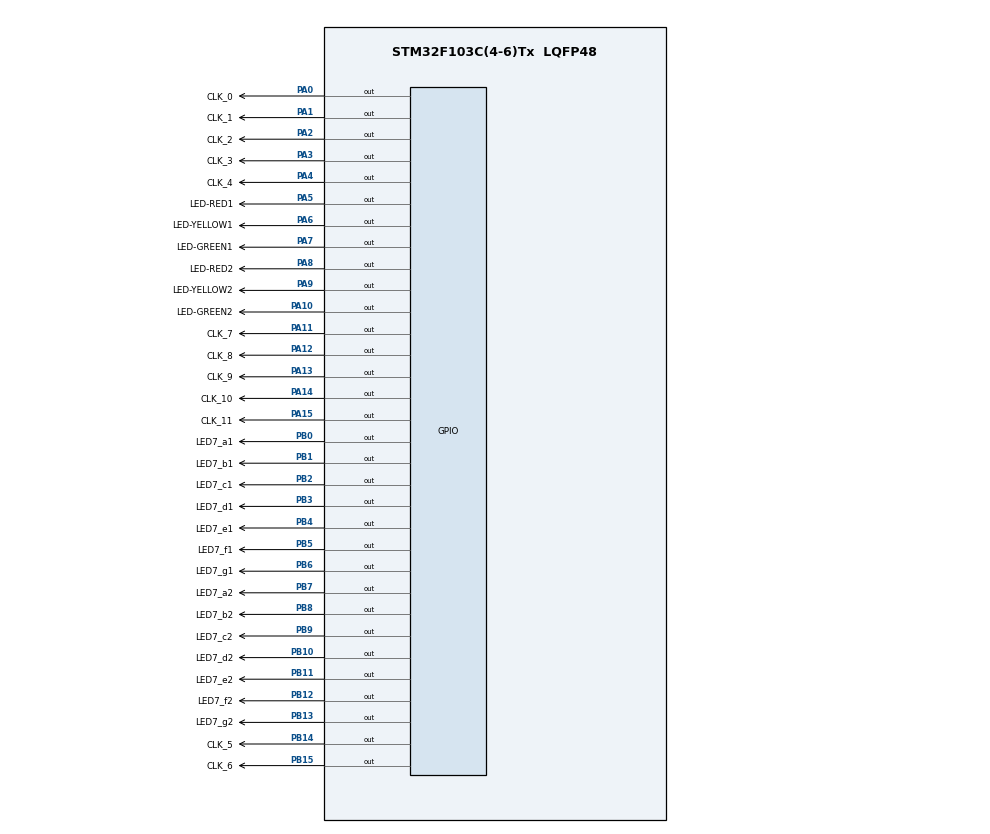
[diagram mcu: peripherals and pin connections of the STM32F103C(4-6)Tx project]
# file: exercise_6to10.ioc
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Mcu.Family=STM32F1
Mcu.Name=STM32F103C(4-6)Tx
Mcu.Package=LQFP48
NVIC.PriorityGroup=NVIC_PRIORITYGROUP_4
PA0-WKUP.GPIO_Label=CLK_0
PA0-WKUP.Signal=GPIO_Output
PA1.GPIO_Label=CLK_1
PA1.Signal=GPIO_Output
PA10.GPIO_Label=LED-GREEN2
PA10.Signal=GPIO_Output
PA11.GPIO_Label=CLK_7
PA11.Signal=GPIO_Output
PA12.GPIO_Label=CLK_8
PA12.Signal=GPIO_Output
PA13.GPIO_Label=CLK_9
PA13.Signal=GPIO_Output
PA14.GPIO_Label=CLK_10
PA14.Signal=GPIO_Output
PA15.GPIO_Label=CLK_11
PA15.Signal=GPIO_Output
PA2.GPIO_Label=CLK_2
PA2.Signal=GPIO_Output
PA3.GPIO_Label=CLK_3
PA3.Signal=GPIO_Output
PA4.GPIO_Label=CLK_4
PA4.Signal=GPIO_Output
PA5.GPIO_Label=LED-RED1
PA5.Signal=GPIO_Output
PA6.GPIO_Label=LED-YELLOW1
PA6.Signal=GPIO_Output
PA7.GPIO_Label=LED-GREEN1
PA7.Signal=GPIO_Output
PA8.GPIO_Label=LED-RED2
PA8.Signal=GPIO_Output
PA9.GPIO_Label=LED-YELLOW2
PA9.Signal=GPIO_Output
PB0.GPIO_Label=LED7_a1
PB0.Signal=GPIO_Output
PB1.GPIO_Label=LED7_b1
PB1.Signal=GPIO_Output
PB10.GPIO_Label=LED7_d2
PB10.Signal=GPIO_Output
PB11.GPIO_Label=LED7_e2
PB11.Signal=GPIO_Output
PB12.GPIO_Label=LED7_f2
PB12.Signal=GPIO_Output
PB13.GPIO_Label=LED7_g2
PB13.Signal=GPIO_Output
PB14.GPIO_Label=CLK_5
PB14.Signal=GPIO_Output
PB15.GPIO_Label=CLK_6
PB15.Signal=GPIO_Output
PB2.GPIO_Label=LED7_c1
PB2.Signal=GPIO_Output
PB3.GPIO_Label=LED7_d1
PB3.Signal=GPIO_Output
PB4.GPIO_Label=LED7_e1
PB4.Signal=GPIO_Output
PB5.GPIO_Label=LED7_f1
PB5.Signal=GPIO_Output
PB6.GPIO_Label=LED7_g1
PB6.Signal=GPIO_Output
PB7.GPIO_Label=LED7_a2
PB7.Signal=GPIO_Output
PB8.GPIO_Label=LED7_b2
PB8.Signal=GPIO_Output
PB9.GPIO_Label=LED7_c2
PB9.Signal=GPIO_Output
ProjectManager.HeapSize=0x200
ProjectManager.StackSize=0x400
ProjectManager.TargetToolchain=STM32CubeIDE
RCC.APB1Freq_Value=8000000
RCC.APB2Freq_Value=8000000
VP_SYS_VS_ND.Mode=No_Debug
board=custom

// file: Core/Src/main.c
/* USER CODE BEGIN Header */
/**
  ******************************************************************************
  * @file           : main.c
  * @brief          : Main program body
  ******************************************************************************
  * @attention
  *
  * <h2><center>&copy; Copyright (c) 2024 STMicroelectronics.
  * All rights reserved.</center></h2>
  *
  * This software component is licensed by ST under BSD 3-Clause license,
  * the "License"; You may not use this file except in compliance with the
  * License. You may obtain a copy of the License at:
  *                        opensource.org/licenses/BSD-3-Clause
  *
  ******************************************************************************
  */
/* USER CODE END Header */
#include "main.h"
#include "exercise_6to10.h"

void SystemClock_Config(void);
static void MX_GPIO_Init(void);

int main(void)
{

  /* MCU Configuration--------------------------------------------------------*/

  /* Reset of all peripherals, Initializes the Flash interface and the Systick. */
  HAL_Init();

  /* Configure the system clock */
  SystemClock_Config();

  /* Initialize all configured peripherals */
  MX_GPIO_Init();

  /* Infinite loop */
  /* USER CODE BEGIN WHILE */
  clearAllClock(); 				// Initial
  while (1)
  {
    /* USER CODE END WHILE */
	displayClock();
	HAL_Delay(10);
  }
}

void SystemClock_Config(void)
{
  RCC_OscInitTypeDef RCC_OscInitStruct = {0};
  RCC_ClkInitTypeDef RCC_ClkInitStruct = {0};

  /** Initializes the RCC Oscillators according to the specified parameters
  * in the RCC_OscInitTypeDef structure.
  */
  RCC_OscInitStruct.OscillatorType = RCC_OSCILLATORTYPE_HSI;
  RCC_OscInitStruct.HSIState = RCC_HSI_ON;
  RCC_OscInitStruct.HSICalibrationValue = RCC_HSICALIBRATION_DEFAULT;
  RCC_OscInitStruct.PLL.PLLState = RCC_PLL_NONE;
  if (HAL_RCC_OscConfig(&RCC_OscInitStruct) != HAL_OK)
  {
    Error_Handler();
  }
  /** Initializes the CPU, AHB and APB buses clocks
  */
  RCC_ClkInitStruct.ClockType = RCC_CLOCKTYPE_HCLK|RCC_CLOCKTYPE_SYSCLK
                              |RCC_CLOCKTYPE_PCLK1|RCC_CLOCKTYPE_PCLK2;
  RCC_ClkInitStruct.SYSCLKSource = RCC_SYSCLKSOURCE_HSI;
  RCC_ClkInitStruct.AHBCLKDivider = RCC_SYSCLK_DIV1;
  RCC_ClkInitStruct.APB1CLKDivider = RCC_HCLK_DIV1;
  RCC_ClkInitStruct.APB2CLKDivider = RCC_HCLK_DIV1;

  if (HAL_RCC_ClockConfig(&RCC_ClkInitStruct, FLASH_LATENCY_0) != HAL_OK)
  {
    Error_Handler();
  }
}

static void MX_GPIO_Init(void)
{
  GPIO_InitTypeDef GPIO_InitStruct = {0};

  /* GPIO Ports Clock Enable */
  __HAL_RCC_GPIOA_CLK_ENABLE();
  __HAL_RCC_GPIOB_CLK_ENABLE();

  /*Configure GPIO pin Output Level */
  HAL_GPIO_WritePin(GPIOA, CLK_0_Pin|CLK_1_Pin|CLK_2_Pin|CLK_3_Pin
                          |CLK_4_Pin|LED_RED1_Pin|LED_YELLOW1_Pin|LED_GREEN1_Pin
                          |LED_RED2_Pin|LED_YELLOW2_Pin|LED_GREEN2_Pin|CLK_7_Pin
                          |CLK_8_Pin|CLK_9_Pin|CLK_10_Pin|CLK_11_Pin, GPIO_PIN_RESET);

  /*Configure GPIO pin Output Level */
  HAL_GPIO_WritePin(GPIOB, LED7_a1_Pin|LED7_b1_Pin|LED7_c1_Pin|LED7_d2_Pin
                          |LED7_e2_Pin|LED7_f2_Pin|LED7_g2_Pin|CLK_5_Pin
                          |CLK_6_Pin|LED7_d1_Pin|LED7_e1_Pin|LED7_f1_Pin
                          |LED7_g1_Pin|LED7_a2_Pin|LED7_b2_Pin|LED7_c2_Pin, GPIO_PIN_RESET);

  /*Configure GPIO pins : CLK_0_Pin CLK_1_Pin CLK_2_Pin CLK_3_Pin
                           CLK_4_Pin LED_RED1_Pin LED_YELLOW1_Pin LED_GREEN1_Pin
                           LED_RED2_Pin LED_YELLOW2_Pin LED_GREEN2_Pin CLK_7_Pin
                           CLK_8_Pin CLK_9_Pin CLK_10_Pin CLK_11_Pin */
  GPIO_InitStruct.Pin = CLK_0_Pin|CLK_1_Pin|CLK_2_Pin|CLK_3_Pin
                          |CLK_4_Pin|LED_RED1_Pin|LED_YELLOW1_Pin|LED_GREEN1_Pin
                          |LED_RED2_Pin|LED_YELLOW2_Pin|LED_GREEN2_Pin|CLK_7_Pin
                          |CLK_8_Pin|CLK_9_Pin|CLK_10_Pin|CLK_11_Pin;
  GPIO_InitStruct.Mode = GPIO_MODE_OUTPUT_PP;
  GPIO_InitStruct.Pull = GPIO_NOPULL;
  GPIO_InitStruct.Speed = GPIO_SPEED_FREQ_LOW;
  HAL_GPIO_Init(GPIOA, &GPIO_InitStruct);

  /*Configure GPIO pins : LED7_a1_Pin LED7_b1_Pin LED7_c1_Pin LED7_d2_Pin
                           LED7_e2_Pin LED7_f2_Pin LED7_g2_Pin CLK_5_Pin
                           CLK_6_Pin LED7_d1_Pin LED7_e1_Pin LED7_f1_Pin
                           LED7_g1_Pin LED7_a2_Pin LED7_b2_Pin LED7_c2_Pin */
  GPIO_InitStruct.Pin = LED7_a1_Pin|LED7_b1_Pin|LED7_c1_Pin|LED7_d2_Pin
                          |LED7_e2_Pin|LED7_f2_Pin|LED7_g2_Pin|CLK_5_Pin
                          |CLK_6_Pin|LED7_d1_Pin|LED7_e1_Pin|LED7_f1_Pin
                          |LED7_g1_Pin|LED7_a2_Pin|LED7_b2_Pin|LED7_c2_Pin;
  GPIO_InitStruct.Mode = GPIO_MODE_OUTPUT_PP;
  GPIO_InitStruct.Pull = GPIO_NOPULL;
  GPIO_InitStruct.Speed = GPIO_SPEED_FREQ_LOW;
  HAL_GPIO_Init(GPIOB, &GPIO_InitStruct);

}

void Error_Handler(void)
{
  __disable_irq();
  while (1)
  {
  }
}

/************************ (C) COPYRIGHT STMicroelectronics *****END OF FILE****/
